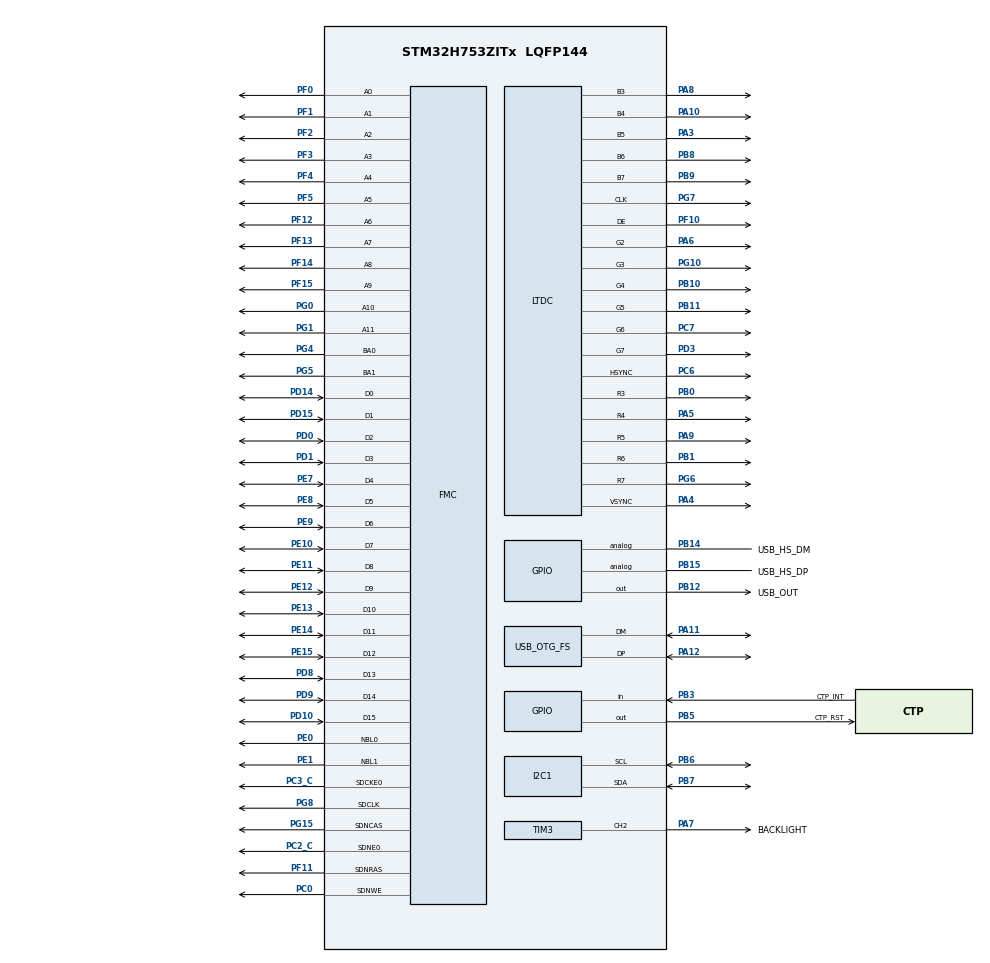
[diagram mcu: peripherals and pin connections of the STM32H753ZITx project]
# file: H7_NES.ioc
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FMC.CASLatency1=FMC_SDRAM_CAS_LATENCY_3
FMC.ExitSelfRefreshDelay1=7
FMC.LoadToActiveDelay1=2
FMC.RCDDelay1=2
FMC.RPDelay1=2
FMC.RPDelay2=2
FMC.ReadPipeDelay1=FMC_SDRAM_RPIPE_DELAY_1
FMC.ReadPipeDelay2=FMC_SDRAM_RPIPE_DELAY_1
FMC.RowCycleDelay1=6
FMC.RowCycleDelay2=6
FMC.SDClockPeriod1=FMC_SDRAM_CLOCK_PERIOD_2
FMC.SDClockPeriod2=FMC_SDRAM_CLOCK_PERIOD_2
FMC.SelfRefreshTime1=4
FMC.WriteRecoveryTime1=2
I2C1.Timing=0x10C0ECFF
LTDC.ActiveW=800
LTDC.Alpha_L0=255
LTDC.BlendingFactor1_L0=LTDC_BLENDING_FACTOR1_PAxCA
LTDC.BlendingFactor1_L1=LTDC_BLENDING_FACTOR1_PAxCA
LTDC.BlendingFactor2_L0=LTDC_BLENDING_FACTOR2_PAxCA
LTDC.BlendingFactor2_L1=LTDC_BLENDING_FACTOR2_PAxCA
LTDC.FBStartAdress_L0=0xC0000000
LTDC.FBStartAdress_L1=0xC00BB800
LTDC.HBP=46
LTDC.HFP=210
LTDC.HSync=10
LTDC.ImageHeight_L0=480
LTDC.ImageHeight_L1=480
LTDC.ImageWidth_L0=800
LTDC.Layers=0
LTDC.PixelFormat_L0=LTDC_PIXEL_FORMAT_RGB565
LTDC.VBP=23
LTDC.VFP=22
LTDC.VSync=10
LTDC.WindowX0_L0=0
LTDC.WindowX1_L0=800
LTDC.WindowX1_L1=800
LTDC.WindowY0_L0=0
LTDC.WindowY1_L0=480
LTDC.WindowY1_L1=480
Mcu.Family=STM32H7
Mcu.Name=STM32H753ZITx
Mcu.Package=LQFP144
NVIC.OTG_FS_IRQn=true\:0\:0\:false\:false\:true\:false\:true\:true
NVIC.PriorityGroup=NVIC_PRIORITYGROUP_4
PA10.Mode=RGB565
PA10.Signal=LTDC_B4
PA11.Mode=Host_Only
PA11.Signal=USB_OTG_FS_DM
PA12.Mode=Host_Only
PA12.Signal=USB_OTG_FS_DP
PA13\ (JTMS/SWDIO).Mode=Serial_Wire
PA13\ (JTMS/SWDIO).Signal=DEBUG_JTMS-SWDIO
PA14\ (JTCK/SWCLK).Mode=Serial_Wire
PA14\ (JTCK/SWCLK).Signal=DEBUG_JTCK-SWCLK
PA3.Mode=RGB565
PA3.Signal=LTDC_B5
PA4.Mode=RGB565
PA4.Signal=LTDC_VSYNC
PA5.Mode=RGB565
PA5.Signal=LTDC_R4
PA6.Mode=RGB565
PA6.Signal=LTDC_G2
PA7.GPIO_Label=BACKLIGHT
PA7.Signal=S_TIM3_CH2
PA8.Mode=RGB565
PA8.Signal=LTDC_B3
PA9.Mode=RGB565
PA9.Signal=LTDC_R5
PB0.Mode=RGB565
PB0.Signal=LTDC_R3
PB1.Mode=RGB565
PB1.Signal=LTDC_R6
PB10.Mode=RGB565
PB10.Signal=LTDC_G4
PB11.Mode=RGB565
PB11.Signal=LTDC_G5
PB12.GPIO_Label=USB_OUT
PB12.Signal=GPIO_Output
PB14.GPIO_Label=USB_HS_DM
PB14.Signal=GPIO_Analog
PB15.GPIO_Label=USB_HS_DP
PB15.Signal=GPIO_Analog
PB3\ (JTDO/TRACESWO).GPIO_Label=CTP_INT
PB3\ (JTDO/TRACESWO).Signal=GPIO_Input
PB5.GPIO_Label=CTP_RST
PB5.Signal=GPIO_Output
PB6.Mode=I2C
PB6.Signal=I2C1_SCL
PB7.Mode=I2C
PB7.Signal=I2C1_SDA
PB8.Mode=RGB565
PB8.Signal=LTDC_B6
PB9.Mode=RGB565
PB9.Signal=LTDC_B7
PC0.Signal=FMC_SDNWE
PC2_C.Mode=SdramChipSelect1_1
PC2_C.Signal=FMC_SDNE0
PC3_C.Mode=SdramChipSelect1_1
PC3_C.Signal=FMC_SDCKE0
PC6.Mode=RGB565
PC6.Signal=LTDC_HSYNC
PC7.Mode=RGB565
PC7.Signal=LTDC_G6
PD0.Signal=FMC_D2_DA2
PD1.Signal=FMC_D3_DA3
PD10.Signal=FMC_D15_DA15
PD14.Signal=FMC_D0_DA0
PD15.Signal=FMC_D1_DA1
PD3.Mode=RGB565
PD3.Signal=LTDC_G7
PD8.Signal=FMC_D13_DA13
PD9.Signal=FMC_D14_DA14
PE0.Signal=FMC_NBL0
PE1.Signal=FMC_NBL1
PE10.Signal=FMC_D7_DA7
PE11.Signal=FMC_D8_DA8
PE12.Signal=FMC_D9_DA9
PE13.Signal=FMC_D10_DA10
PE14.Signal=FMC_D11_DA11
PE15.Signal=FMC_D12_DA12
PE7.Signal=FMC_D4_DA4
PE8.Signal=FMC_D5_DA5
PE9.Signal=FMC_D6_DA6
PF0.Signal=FMC_A0
PF1.Signal=FMC_A1
PF10.Mode=RGB565
PF10.Signal=LTDC_DE
PF11.Signal=FMC_SDNRAS
PF12.Signal=FMC_A6
PF13.Signal=FMC_A7
PF14.Signal=FMC_A8
PF15.Signal=FMC_A9
PF2.Signal=FMC_A2
PF3.Signal=FMC_A3
PF4.Signal=FMC_A4
PF5.Signal=FMC_A5
PG0.Signal=FMC_A10
PG1.Signal=FMC_A11
PG10.Mode=RGB565
PG10.Signal=LTDC_G3
PG15.Signal=FMC_SDNCAS
PG4.Signal=FMC_A14_BA0
PG5.Signal=FMC_A15_BA1
PG6.Mode=RGB565
PG6.Signal=LTDC_R7
PG7.Mode=RGB565
PG7.Signal=LTDC_CLK
PG8.Signal=FMC_SDCLK
PH0-OSC_IN\ (PH0).Mode=HSE-External-Oscillator
PH0-OSC_IN\ (PH0).Signal=RCC_OSC_IN
PH1-OSC_OUT\ (PH1).Mode=HSE-External-Oscillator
PH1-OSC_OUT\ (PH1).Signal=RCC_OSC_OUT
ProjectManager.HeapSize=0x200
ProjectManager.StackSize=0x400
ProjectManager.TargetToolchain=STM32CubeIDE
RCC.ADCFreq_Value=240000000
RCC.APB1Freq_Value=100000000
RCC.APB2Freq_Value=100000000
RCC.APB3Freq_Value=100000000
RCC.APB4Freq_Value=100000000
RCC.CortexFreq_Value=400000000
RCC.D1PPRE=RCC_APB3_DIV2
RCC.D2PPRE1=RCC_APB1_DIV2
RCC.D2PPRE2=RCC_APB2_DIV2
RCC.D3PPRE=RCC_APB4_DIV2
RCC.DIVM1=1
RCC.DIVM2=2
RCC.DIVM3=1
RCC.DIVN1=100
RCC.DIVN2=120
RCC.DIVN3=18
RCC.DIVQ1=4
RCC.DIVR3=10
RCC.HCLKFreq_Value=200000000
RCC.HPRE=RCC_HCLK_DIV2
RCC.HSE_VALUE=8000000
RCC.PLL2FRACN=0
RCC.PLL3FRACN=6144
RCC.PLLFRACN=0
RCC.PLLSourceVirtual=RCC_PLLSOURCE_HSE
RCC.PWR_Regulator_Voltage_Scale=PWR_REGULATOR_VOLTAGE_SCALE1
RCC.SYSCLKFreq_VALUE=400000000
RCC.SYSCLKSource=RCC_SYSCLKSOURCE_PLLCLK
RCC.USBCLockSelection=RCC_USBCLKSOURCE_HSI48
RCC.USBFreq_Value=48000000
SH.FMC_A0.0=FMC_A0,12b-sda1
SH.FMC_A1.0=FMC_A1,12b-sda1
SH.FMC_A10.0=FMC_A10,12b-sda1
SH.FMC_A11.0=FMC_A11,12b-sda1
SH.FMC_A14_BA0.0=FMC_BA0,FourSdramBanks1
SH.FMC_A15_BA1.0=FMC_BA1,FourSdramBanks1
SH.FMC_A2.0=FMC_A2,12b-sda1
SH.FMC_A3.0=FMC_A3,12b-sda1
SH.FMC_A4.0=FMC_A4,12b-sda1
SH.FMC_A5.0=FMC_A5,12b-sda1
SH.FMC_A6.0=FMC_A6,12b-sda1
SH.FMC_A7.0=FMC_A7,12b-sda1
SH.FMC_A8.0=FMC_A8,12b-sda1
SH.FMC_A9.0=FMC_A9,12b-sda1
SH.FMC_D0_DA0.0=FMC_D0,sd-16b-d1
SH.FMC_D10_DA10.0=FMC_D10,sd-16b-d1
SH.FMC_D11_DA11.0=FMC_D11,sd-16b-d1
SH.FMC_D12_DA12.0=FMC_D12,sd-16b-d1
SH.FMC_D13_DA13.0=FMC_D13,sd-16b-d1
SH.FMC_D14_DA14.0=FMC_D14,sd-16b-d1
SH.FMC_D15_DA15.0=FMC_D15,sd-16b-d1
SH.FMC_D1_DA1.0=FMC_D1,sd-16b-d1
SH.FMC_D2_DA2.0=FMC_D2,sd-16b-d1
SH.FMC_D3_DA3.0=FMC_D3,sd-16b-d1
SH.FMC_D4_DA4.0=FMC_D4,sd-16b-d1
SH.FMC_D5_DA5.0=FMC_D5,sd-16b-d1
SH.FMC_D6_DA6.0=FMC_D6,sd-16b-d1
SH.FMC_D7_DA7.0=FMC_D7,sd-16b-d1
SH.FMC_D8_DA8.0=FMC_D8,sd-16b-d1
SH.FMC_D9_DA9.0=FMC_D9,sd-16b-d1
SH.FMC_NBL0.0=FMC_NBL0,Sd2ByteEnable1
SH.FMC_NBL1.0=FMC_NBL1,Sd2ByteEnable1
SH.FMC_SDCLK.0=FMC_SDCLK,12b-sda1
SH.FMC_SDNCAS.0=FMC_SDNCAS,12b-sda1
SH.FMC_SDNRAS.0=FMC_SDNRAS,12b-sda1
SH.FMC_SDNWE.0=FMC_SDNWE,12b-sda1
SH.S_TIM3_CH2.0=TIM3_CH2,PWM Generation2 CH2
TIM3.Channel-PWM\ Generation2\ CH2=TIM_CHANNEL_2
TIM3.Period=1023
TIM3.Prescaler=120
TIM3.Pulse-PWM\ Generation2\ CH2=800
USB_HOST.BSP.number=1
USB_HOST.USBH_HandleTypeDef-ALL_Classes_FS=hUsbHostFS
USB_HOST.VirtualModeFS=All_Classes
USB_HOST0.BSP.STBoard=false
USB_HOST0.BSP.api=Unknown
USB_HOST0.BSP.instance=PB12
USB_HOST0.BSP.ip=GPIO
USB_HOST0.BSP.mode=Output
USB_HOST0.BSP.name=Drive_VBUS_FS
USB_HOST0.BSP.solution=PB12
USB_OTG_FS.VirtualMode=Host_Only
USB_OTG_FS.phy_itface=HCD_PHY_EMBEDDED
VP_DMA2D_VS_DMA2D.Mode=DMA2D_Activate
VP_USB_HOST_VS_USB_HOST_ALL_CLASS_FS.Mode=ALL_Classes_FS
board=custom

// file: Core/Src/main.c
/* USER CODE BEGIN Header */
/**
 ******************************************************************************
 * @file           : main.c
 * @brief          : Main program body
 ******************************************************************************
 * @attention
 *
 * Copyright (c) 2023 STMicroelectronics.
 * All rights reserved.
 *
 * This software is licensed under terms that can be found in the LICENSE file
 * in the root directory of this software component.
 * If no LICENSE file comes with this software, it is provided AS-IS.
 *
 ******************************************************************************
 */
/* USER CODE END Header */
#include "main.h"
#include "usb_host.h"

/* USER CODE BEGIN Includes */
#include "nes.h"

/* USER CODE END Includes */

/* USER CODE BEGIN PTD */
extern uint16_t * framebuffer;
/* USER CODE END PTD */

DMA2D_HandleTypeDef hdma2d;

I2C_HandleTypeDef hi2c1;

LTDC_HandleTypeDef hltdc;

TIM_HandleTypeDef htim3;

SDRAM_HandleTypeDef hsdram1;

void SystemClock_Config(void);
static void MX_GPIO_Init(void);
static void MX_FMC_Init(void);
static void MX_I2C1_Init(void);
static void MX_LTDC_Init(void);
static void MX_TIM3_Init(void);
static void MX_DMA2D_Init(void);
void MX_USB_HOST_Process(void);

/* USER CODE BEGIN PFP */
extern const uint8_t MAIO[];

/* USER CODE END PFP */

int main(void)
{

  /* MCU Configuration--------------------------------------------------------*/

  /* Reset of all peripherals, Initializes the Flash interface and the Systick. */
  HAL_Init();

  /* USER CODE BEGIN Init */
#if 1
  /* USER CODE END Init */

  /* Configure the system clock */
  SystemClock_Config();

  /* USER CODE BEGIN SysInit */
#endif

	//SystemClock_Config_HSI();

  /* USER CODE END SysInit */

  /* Initialize all configured peripherals */
  MX_GPIO_Init();
  MX_FMC_Init();
  MX_I2C1_Init();
  MX_LTDC_Init();
  MX_TIM3_Init();
  MX_USB_HOST_Init();
  MX_DMA2D_Init();
  /* USER CODE BEGIN 2 */

	HAL_TIM_PWM_Start(&htim3, TIM_CHANNEL_2);

	  for(int y = 0; y < 479; y++)
	  {
		  for(int x = 0; x < 799; x++)
		  {
			  framebuffer[y * 799 + x] = 0;
		  }
	  }

	  nofrendo_start(MAIO, NES_NTSC, 4800, 0);

  /* USER CODE END 2 */

  /* Infinite loop */
	while (1)
	{
    MX_USB_HOST_Process();

	}
}

void SystemClock_Config(void)
{
  RCC_OscInitTypeDef RCC_OscInitStruct = {0};
  RCC_ClkInitTypeDef RCC_ClkInitStruct = {0};

  /** Supply configuration update enable
  */
  HAL_PWREx_ConfigSupply(PWR_LDO_SUPPLY);

  /** Configure the main internal regulator output voltage
  */
  __HAL_PWR_VOLTAGESCALING_CONFIG(PWR_REGULATOR_VOLTAGE_SCALE1);

  while(!__HAL_PWR_GET_FLAG(PWR_FLAG_VOSRDY)) {}

  /** Initializes the RCC Oscillators according to the specified parameters
  * in the RCC_OscInitTypeDef structure.
  */
  RCC_OscInitStruct.OscillatorType = RCC_OSCILLATORTYPE_HSI48|RCC_OSCILLATORTYPE_HSE;
  RCC_OscInitStruct.HSEState = RCC_HSE_ON;
  RCC_OscInitStruct.HSI48State = RCC_HSI48_ON;
  RCC_OscInitStruct.PLL.PLLState = RCC_PLL_ON;
  RCC_OscInitStruct.PLL.PLLSource = RCC_PLLSOURCE_HSE;
  RCC_OscInitStruct.PLL.PLLM = 1;
  RCC_OscInitStruct.PLL.PLLN = 100;
  RCC_OscInitStruct.PLL.PLLP = 2;
  RCC_OscInitStruct.PLL.PLLQ = 4;
  RCC_OscInitStruct.PLL.PLLR = 2;
  RCC_OscInitStruct.PLL.PLLRGE = RCC_PLL1VCIRANGE_3;
  RCC_OscInitStruct.PLL.PLLVCOSEL = RCC_PLL1VCOWIDE;
  RCC_OscInitStruct.PLL.PLLFRACN = 0;
  if (HAL_RCC_OscConfig(&RCC_OscInitStruct) != HAL_OK)
  {
    Error_Handler();
  }

  /** Initializes the CPU, AHB and APB buses clocks
  */
  RCC_ClkInitStruct.ClockType = RCC_CLOCKTYPE_HCLK|RCC_CLOCKTYPE_SYSCLK
                              |RCC_CLOCKTYPE_PCLK1|RCC_CLOCKTYPE_PCLK2
                              |RCC_CLOCKTYPE_D3PCLK1|RCC_CLOCKTYPE_D1PCLK1;
  RCC_ClkInitStruct.SYSCLKSource = RCC_SYSCLKSOURCE_PLLCLK;
  RCC_ClkInitStruct.SYSCLKDivider = RCC_SYSCLK_DIV1;
  RCC_ClkInitStruct.AHBCLKDivider = RCC_HCLK_DIV2;
  RCC_ClkInitStruct.APB3CLKDivider = RCC_APB3_DIV2;
  RCC_ClkInitStruct.APB1CLKDivider = RCC_APB1_DIV2;
  RCC_ClkInitStruct.APB2CLKDivider = RCC_APB2_DIV2;
  RCC_ClkInitStruct.APB4CLKDivider = RCC_APB4_DIV2;

  if (HAL_RCC_ClockConfig(&RCC_ClkInitStruct, FLASH_LATENCY_2) != HAL_OK)
  {
    Error_Handler();
  }
}

static void MX_DMA2D_Init(void)
{

  hdma2d.Instance = DMA2D;
  hdma2d.Init.Mode = DMA2D_M2M;
  hdma2d.Init.ColorMode = DMA2D_OUTPUT_ARGB8888;
  hdma2d.Init.OutputOffset = 0;
  hdma2d.LayerCfg[1].InputOffset = 0;
  hdma2d.LayerCfg[1].InputColorMode = DMA2D_INPUT_ARGB8888;
  hdma2d.LayerCfg[1].AlphaMode = DMA2D_NO_MODIF_ALPHA;
  hdma2d.LayerCfg[1].InputAlpha = 0;
  hdma2d.LayerCfg[1].AlphaInverted = DMA2D_REGULAR_ALPHA;
  hdma2d.LayerCfg[1].RedBlueSwap = DMA2D_RB_REGULAR;
  hdma2d.LayerCfg[1].ChromaSubSampling = DMA2D_NO_CSS;
  if (HAL_DMA2D_Init(&hdma2d) != HAL_OK)
  {
    Error_Handler();
  }
  if (HAL_DMA2D_ConfigLayer(&hdma2d, 1) != HAL_OK)
  {
    Error_Handler();
  }

}

static void MX_I2C1_Init(void)
{

  hi2c1.Instance = I2C1;
  hi2c1.Init.Timing = 0x10C0ECFF;
  hi2c1.Init.OwnAddress1 = 0;
  hi2c1.Init.AddressingMode = I2C_ADDRESSINGMODE_7BIT;
  hi2c1.Init.DualAddressMode = I2C_DUALADDRESS_DISABLE;
  hi2c1.Init.OwnAddress2 = 0;
  hi2c1.Init.OwnAddress2Masks = I2C_OA2_NOMASK;
  hi2c1.Init.GeneralCallMode = I2C_GENERALCALL_DISABLE;
  hi2c1.Init.NoStretchMode = I2C_NOSTRETCH_DISABLE;
  if (HAL_I2C_Init(&hi2c1) != HAL_OK)
  {
    Error_Handler();
  }

  /** Configure Analogue filter
  */
  if (HAL_I2CEx_ConfigAnalogFilter(&hi2c1, I2C_ANALOGFILTER_ENABLE) != HAL_OK)
  {
    Error_Handler();
  }

  /** Configure Digital filter
  */
  if (HAL_I2CEx_ConfigDigitalFilter(&hi2c1, 0) != HAL_OK)
  {
    Error_Handler();
  }

}

static void MX_LTDC_Init(void)
{

  LTDC_LayerCfgTypeDef pLayerCfg = {0};

  hltdc.Instance = LTDC;
  hltdc.Init.HSPolarity = LTDC_HSPOLARITY_AL;
  hltdc.Init.VSPolarity = LTDC_VSPOLARITY_AL;
  hltdc.Init.DEPolarity = LTDC_DEPOLARITY_AL;
  hltdc.Init.PCPolarity = LTDC_PCPOLARITY_IPC;
  hltdc.Init.HorizontalSync = 9;
  hltdc.Init.VerticalSync = 9;
  hltdc.Init.AccumulatedHBP = 55;
  hltdc.Init.AccumulatedVBP = 32;
  hltdc.Init.AccumulatedActiveW = 855;
  hltdc.Init.AccumulatedActiveH = 512;
  hltdc.Init.TotalWidth = 1065;
  hltdc.Init.TotalHeigh = 534;
  hltdc.Init.Backcolor.Blue = 0;
  hltdc.Init.Backcolor.Green = 0;
  hltdc.Init.Backcolor.Red = 0;
  if (HAL_LTDC_Init(&hltdc) != HAL_OK)
  {
    Error_Handler();
  }
  pLayerCfg.WindowX0 = 0;
  pLayerCfg.WindowX1 = 800;
  pLayerCfg.WindowY0 = 0;
  pLayerCfg.WindowY1 = 480;
  pLayerCfg.PixelFormat = LTDC_PIXEL_FORMAT_RGB565;
  pLayerCfg.Alpha = 255;
  pLayerCfg.Alpha0 = 0;
  pLayerCfg.BlendingFactor1 = LTDC_BLENDING_FACTOR1_PAxCA;
  pLayerCfg.BlendingFactor2 = LTDC_BLENDING_FACTOR2_PAxCA;
  pLayerCfg.FBStartAdress = 0xC0000000;
  pLayerCfg.ImageWidth = 800;
  pLayerCfg.ImageHeight = 480;
  pLayerCfg.Backcolor.Blue = 0;
  pLayerCfg.Backcolor.Green = 0;
  pLayerCfg.Backcolor.Red = 0;
  if (HAL_LTDC_ConfigLayer(&hltdc, &pLayerCfg, 0) != HAL_OK)
  {
    Error_Handler();
  }

}

static void MX_TIM3_Init(void)
{

  TIM_MasterConfigTypeDef sMasterConfig = {0};
  TIM_OC_InitTypeDef sConfigOC = {0};

  htim3.Instance = TIM3;
  htim3.Init.Prescaler = 120;
  htim3.Init.CounterMode = TIM_COUNTERMODE_UP;
  htim3.Init.Period = 1023;
  htim3.Init.ClockDivision = TIM_CLOCKDIVISION_DIV1;
  htim3.Init.AutoReloadPreload = TIM_AUTORELOAD_PRELOAD_DISABLE;
  if (HAL_TIM_PWM_Init(&htim3) != HAL_OK)
  {
    Error_Handler();
  }
  sMasterConfig.MasterOutputTrigger = TIM_TRGO_RESET;
  sMasterConfig.MasterSlaveMode = TIM_MASTERSLAVEMODE_DISABLE;
  if (HAL_TIMEx_MasterConfigSynchronization(&htim3, &sMasterConfig) != HAL_OK)
  {
    Error_Handler();
  }
  sConfigOC.OCMode = TIM_OCMODE_PWM1;
  sConfigOC.Pulse = 800;
  sConfigOC.OCPolarity = TIM_OCPOLARITY_HIGH;
  sConfigOC.OCFastMode = TIM_OCFAST_DISABLE;
  if (HAL_TIM_PWM_ConfigChannel(&htim3, &sConfigOC, TIM_CHANNEL_2) != HAL_OK)
  {
    Error_Handler();
  }
  HAL_TIM_MspPostInit(&htim3);

}

/* FMC initialization function */
static void MX_FMC_Init(void)
{

  /* USER CODE BEGIN FMC_Init 0 */
	#define REFRESH_COUNT                    		((uint32_t)0x0583)   /* SDRAM refresh counter (100Mhz SD clock) */
	#define SDRAM_TIMEOUT                    		((uint32_t)0xFFFF)
		// FMC SDRAM Mode definition register defines
	#define SDRAM_MODEREG_BURST_LENGTH_1             ((uint16_t)0x0000)
	#define SDRAM_MODEREG_BURST_LENGTH_2             ((uint16_t)0x0001)
	#define SDRAM_MODEREG_BURST_LENGTH_4             ((uint16_t)0x0002)
	#define SDRAM_MODEREG_BURST_LENGTH_8             ((uint16_t)0x0004)
	#define SDRAM_MODEREG_BURST_TYPE_SEQUENTIAL      ((uint16_t)0x0000)
	#define SDRAM_MODEREG_BURST_TYPE_INTERLEAVED     ((uint16_t)0x0008)
	#define SDRAM_MODEREG_CAS_LATENCY_2              ((uint16_t)0x0020)
	#define SDRAM_MODEREG_CAS_LATENCY_3              ((uint16_t)0x0030)
	#define SDRAM_MODEREG_OPERATING_MODE_STANDARD    ((uint16_t)0x0000)
	#define SDRAM_MODEREG_WRITEBURST_MODE_PROGRAMMED ((uint16_t)0x0000)
	#define SDRAM_MODEREG_WRITEBURST_MODE_SINGLE     ((uint16_t)0x0200)
		static FMC_SDRAM_CommandTypeDef Command;
  /* USER CODE END FMC_Init 0 */

  FMC_SDRAM_TimingTypeDef SdramTiming = {0};

  /** Perform the SDRAM1 memory initialization sequence
  */
  hsdram1.Instance = FMC_SDRAM_DEVICE;
  /* hsdram1.Init */
  hsdram1.Init.SDBank = FMC_SDRAM_BANK1;
  hsdram1.Init.ColumnBitsNumber = FMC_SDRAM_COLUMN_BITS_NUM_8;
  hsdram1.Init.RowBitsNumber = FMC_SDRAM_ROW_BITS_NUM_12;
  hsdram1.Init.MemoryDataWidth = FMC_SDRAM_MEM_BUS_WIDTH_16;
  hsdram1.Init.InternalBankNumber = FMC_SDRAM_INTERN_BANKS_NUM_4;
  hsdram1.Init.CASLatency = FMC_SDRAM_CAS_LATENCY_3;
  hsdram1.Init.WriteProtection = FMC_SDRAM_WRITE_PROTECTION_DISABLE;
  hsdram1.Init.SDClockPeriod = FMC_SDRAM_CLOCK_PERIOD_2;
  hsdram1.Init.ReadBurst = FMC_SDRAM_RBURST_DISABLE;
  hsdram1.Init.ReadPipeDelay = FMC_SDRAM_RPIPE_DELAY_1;
  /* SdramTiming */
  SdramTiming.LoadToActiveDelay = 2;
  SdramTiming.ExitSelfRefreshDelay = 7;
  SdramTiming.SelfRefreshTime = 4;
  SdramTiming.RowCycleDelay = 6;
  SdramTiming.WriteRecoveryTime = 2;
  SdramTiming.RPDelay = 2;
  SdramTiming.RCDDelay = 2;

  if (HAL_SDRAM_Init(&hsdram1, &SdramTiming) != HAL_OK)
  {
    Error_Handler( );
  }

  /* USER CODE BEGIN FMC_Init 2 */
		__IO uint32_t tmpmrd = 0;

		/* Step 1: Configure a clock configuration enable command */
		Command.CommandMode            = FMC_SDRAM_CMD_CLK_ENABLE;
		Command.CommandTarget          =  FMC_SDRAM_CMD_TARGET_BANK1;
		Command.AutoRefreshNumber      = 1;
		Command.ModeRegisterDefinition = 0;

		/* Send the command */
		HAL_SDRAM_SendCommand(&hsdram1, &Command, SDRAM_TIMEOUT);

		/* Step 2: Insert 100 us minimum delay */
		/* Inserted delay is equal to 1 ms due to systick time base unit (ms) */
		HAL_Delay(1);

		/* Step 3: Configure a PALL (precharge all) command */
		Command.CommandMode            = FMC_SDRAM_CMD_PALL;
		Command.CommandTarget          = FMC_SDRAM_CMD_TARGET_BANK1;
		Command.AutoRefreshNumber      = 1;
		Command.ModeRegisterDefinition = 0;

		/* Send the command */
		HAL_SDRAM_SendCommand(&hsdram1, &Command, SDRAM_TIMEOUT);

		/* Step 4: Configure an Auto Refresh command */
		Command.CommandMode            = FMC_SDRAM_CMD_AUTOREFRESH_MODE;
		Command.CommandTarget          = FMC_SDRAM_CMD_TARGET_BANK1;
		Command.AutoRefreshNumber      = 8;
		Command.ModeRegisterDefinition = 0;

		/* Send the command */
		HAL_SDRAM_SendCommand(&hsdram1, &Command, SDRAM_TIMEOUT);

		/* Step 5: Program the external memory mode register */
		tmpmrd = (uint32_t)SDRAM_MODEREG_BURST_LENGTH_1          |\
				SDRAM_MODEREG_BURST_TYPE_SEQUENTIAL   |\
				SDRAM_MODEREG_CAS_LATENCY_3           |\
				SDRAM_MODEREG_OPERATING_MODE_STANDARD |\
				SDRAM_MODEREG_WRITEBURST_MODE_SINGLE;

		Command.CommandMode            = FMC_SDRAM_CMD_LOAD_MODE;
		Command.CommandTarget          = FMC_SDRAM_CMD_TARGET_BANK1;
		Command.AutoRefreshNumber      = 1;
		Command.ModeRegisterDefinition = tmpmrd;

		/* Send the command */
		HAL_SDRAM_SendCommand(&hsdram1, &Command, SDRAM_TIMEOUT);

		/* Step 6: Set the refresh rate counter */
		/* Set the device refresh rate */
		HAL_SDRAM_ProgramRefreshRate(&hsdram1, REFRESH_COUNT);
  /* USER CODE END FMC_Init 2 */
}

static void MX_GPIO_Init(void)
{
  GPIO_InitTypeDef GPIO_InitStruct = {0};

  /* GPIO Ports Clock Enable */
  __HAL_RCC_GPIOF_CLK_ENABLE();
  __HAL_RCC_GPIOH_CLK_ENABLE();
  __HAL_RCC_GPIOC_CLK_ENABLE();
  __HAL_RCC_GPIOA_CLK_ENABLE();
  __HAL_RCC_GPIOB_CLK_ENABLE();
  __HAL_RCC_GPIOG_CLK_ENABLE();
  __HAL_RCC_GPIOE_CLK_ENABLE();
  __HAL_RCC_GPIOD_CLK_ENABLE();

  /*Configure GPIO pin Output Level */
  HAL_GPIO_WritePin(GPIOB, USB_OUT_Pin|CTP_RST_Pin, GPIO_PIN_RESET);

  /*Configure GPIO pins : USB_OUT_Pin CTP_RST_Pin */
  GPIO_InitStruct.Pin = USB_OUT_Pin|CTP_RST_Pin;
  GPIO_InitStruct.Mode = GPIO_MODE_OUTPUT_PP;
  GPIO_InitStruct.Pull = GPIO_NOPULL;
  GPIO_InitStruct.Speed = GPIO_SPEED_FREQ_LOW;
  HAL_GPIO_Init(GPIOB, &GPIO_InitStruct);

  /*Configure GPIO pins : USB_HS_DM_Pin USB_HS_DP_Pin */
  GPIO_InitStruct.Pin = USB_HS_DM_Pin|USB_HS_DP_Pin;
  GPIO_InitStruct.Mode = GPIO_MODE_ANALOG;
  GPIO_InitStruct.Pull = GPIO_NOPULL;
  HAL_GPIO_Init(GPIOB, &GPIO_InitStruct);

  /*Configure GPIO pin : CTP_INT_Pin */
  GPIO_InitStruct.Pin = CTP_INT_Pin;
  GPIO_InitStruct.Mode = GPIO_MODE_INPUT;
  GPIO_InitStruct.Pull = GPIO_NOPULL;
  HAL_GPIO_Init(CTP_INT_GPIO_Port, &GPIO_InitStruct);

}

/* USER CODE BEGIN 4 */

void SystemClock_Config_HSI(void)
{
	RCC_OscInitTypeDef RCC_OscInitStruct = {0};
	RCC_ClkInitTypeDef RCC_ClkInitStruct = {0};

	/** Supply configuration update enable
	 */
	HAL_PWREx_ConfigSupply(PWR_LDO_SUPPLY);
	/** Configure the main internal regulator output voltage
	 */
	__HAL_PWR_VOLTAGESCALING_CONFIG(PWR_REGULATOR_VOLTAGE_SCALE0);

	while(!__HAL_PWR_GET_FLAG(PWR_FLAG_VOSRDY)) {}
	/** Macro to configure the PLL clock source
	 */
	__HAL_RCC_PLL_PLLSOURCE_CONFIG(RCC_PLLSOURCE_HSI);
	/** Initializes the RCC Oscillators according to the specified parameters
	 * in the RCC_OscInitTypeDef structure.
	 */
	RCC_OscInitStruct.OscillatorType = RCC_OSCILLATORTYPE_HSI48|RCC_OSCILLATORTYPE_HSI
			|RCC_OSCILLATORTYPE_LSI;
	RCC_OscInitStruct.HSIState = RCC_HSI_DIV8;
	RCC_OscInitStruct.HSICalibrationValue = RCC_HSICALIBRATION_DEFAULT;
	RCC_OscInitStruct.LSIState = RCC_LSI_ON;
	RCC_OscInitStruct.HSI48State = RCC_HSI48_ON;
	RCC_OscInitStruct.PLL.PLLState = RCC_PLL_ON;
	RCC_OscInitStruct.PLL.PLLSource = RCC_PLLSOURCE_HSI;
	RCC_OscInitStruct.PLL.PLLM = 1;
	RCC_OscInitStruct.PLL.PLLN = 120;
	RCC_OscInitStruct.PLL.PLLP = 2;
	RCC_OscInitStruct.PLL.PLLQ = 4;
	RCC_OscInitStruct.PLL.PLLR = 2;
	RCC_OscInitStruct.PLL.PLLRGE = RCC_PLL1VCIRANGE_3;
	RCC_OscInitStruct.PLL.PLLVCOSEL = RCC_PLL1VCOWIDE;
	RCC_OscInitStruct.PLL.PLLFRACN = 0;
	if (HAL_RCC_OscConfig(&RCC_OscInitStruct) != HAL_OK)
	{
		Error_Handler();
	}
	/** Initializes the CPU, AHB and APB buses clocks
	 */
	RCC_ClkInitStruct.ClockType = RCC_CLOCKTYPE_HCLK|RCC_CLOCKTYPE_SYSCLK
			|RCC_CLOCKTYPE_PCLK1|RCC_CLOCKTYPE_PCLK2
			|RCC_CLOCKTYPE_D3PCLK1|RCC_CLOCKTYPE_D1PCLK1;
	RCC_ClkInitStruct.SYSCLKSource = RCC_SYSCLKSOURCE_PLLCLK;
	RCC_ClkInitStruct.SYSCLKDivider = RCC_SYSCLK_DIV1;
	RCC_ClkInitStruct.AHBCLKDivider = RCC_HCLK_DIV2;
	RCC_ClkInitStruct.APB3CLKDivider = RCC_APB3_DIV2;
	RCC_ClkInitStruct.APB1CLKDivider = RCC_APB1_DIV2;
	RCC_ClkInitStruct.APB2CLKDivider = RCC_APB2_DIV2;
	RCC_ClkInitStruct.APB4CLKDivider = RCC_APB4_DIV2;

	if (HAL_RCC_ClockConfig(&RCC_ClkInitStruct, FLASH_LATENCY_4) != HAL_OK)
	{
		Error_Handler();
	}
}

/* USER CODE END 4 */

void Error_Handler(void)
{
	__disable_irq();
	while (1)
	{
	}
}
